# MSPM0G150X register map
Vendor: Texas Instruments; File version: This preliminary header file does not have a version number - build date: 2023-02-21 16:25:48
CPU: CM0 r0p1, little endian, MPU, no FPU, 3 interrupt priority bits
Registers are 32-bit, read-write, reset 0x0 unless marked. A register's access mark holds for its fields unless they carry their own. Offsets are from the block's base; [hi:lo] are bit positions; {n}, {i} and the like mark numbered series; <NAME> marks a mode.

## I2C0 (part 2 of 2) — PERIPHERALREGION
Base 0x400F0000
Same registers: I2C1 0x400F2000
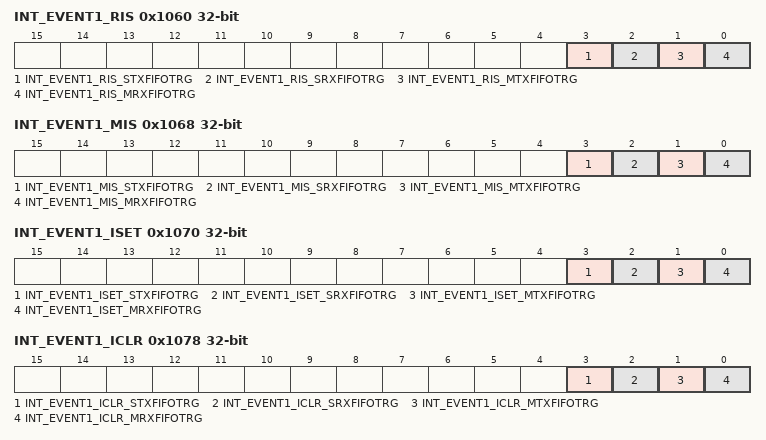
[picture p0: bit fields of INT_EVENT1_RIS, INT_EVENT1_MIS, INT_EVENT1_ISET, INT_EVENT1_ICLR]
0x1060 INT_EVENT1_RIS ro — Raw interrupt status
  [3] INT_EVENT1_RIS_STXFIFOTRG — Slave Transmit FIFO Trigger
    0=INT_EVENT1_RIS_STXFIFOTRG_CLR (CLR); 1=INT_EVENT1_RIS_STXFIFOTRG_SET (SET)
  [2] INT_EVENT1_RIS_SRXFIFOTRG — Slave Receive FIFO Trigger
    0=INT_EVENT1_RIS_SRXFIFOTRG_CLR (CLR); 1=INT_EVENT1_RIS_SRXFIFOTRG_SET (SET)
  [1] INT_EVENT1_RIS_MTXFIFOTRG — Master Transmit FIFO Trigger Trigger when Transmit FIFO contains <= defined bytes
    0=INT_EVENT1_RIS_MTXFIFOTRG_CLR (CLR); 1=INT_EVENT1_RIS_MTXFIFOTRG_SET (SET)
  [0] INT_EVENT1_RIS_MRXFIFOTRG — Master Receive FIFO Trigger Trigger when RX FIFO contains >= defined bytes
    0=INT_EVENT1_RIS_MRXFIFOTRG_CLR (CLR); 1=INT_EVENT1_RIS_MRXFIFOTRG_SET (SET)
0x1068 INT_EVENT1_MIS ro — Masked interrupt status
  [3] INT_EVENT1_MIS_STXFIFOTRG — Slave Transmit FIFO Trigger
    0=INT_EVENT1_MIS_STXFIFOTRG_CLR (CLR); 1=INT_EVENT1_MIS_STXFIFOTRG_SET (SET)
  [2] INT_EVENT1_MIS_SRXFIFOTRG — Slave Receive FIFO Trigger
    0=INT_EVENT1_MIS_SRXFIFOTRG_CLR (CLR); 1=INT_EVENT1_MIS_SRXFIFOTRG_SET (SET)
  [1] INT_EVENT1_MIS_MTXFIFOTRG — Master Transmit FIFO Trigger Trigger when Transmit FIFO contains <= defined bytes
    0=INT_EVENT1_MIS_MTXFIFOTRG_CLR (CLR); 1=INT_EVENT1_MIS_MTXFIFOTRG_SET (SET)
  [0] INT_EVENT1_MIS_MRXFIFOTRG — Master Receive FIFO Trigger Trigger when RX FIFO contains >= defined bytes
    0=INT_EVENT1_MIS_MRXFIFOTRG_CLR (CLR); 1=INT_EVENT1_MIS_MRXFIFOTRG_SET (SET)
0x1070 INT_EVENT1_ISET wo — Interrupt set
  [3] INT_EVENT1_ISET_STXFIFOTRG — Slave Transmit FIFO Trigger
    0=INT_EVENT1_ISET_STXFIFOTRG_NO_EFFECT (NO_EFFECT); 1=INT_EVENT1_ISET_STXFIFOTRG_SET (SET)
  [2] INT_EVENT1_ISET_SRXFIFOTRG — Slave Receive FIFO Trigger
    0=INT_EVENT1_ISET_SRXFIFOTRG_NO_EFFECT (NO_EFFECT); 1=INT_EVENT1_ISET_SRXFIFOTRG_SET (SET)
  [1] INT_EVENT1_ISET_MTXFIFOTRG — Master Transmit FIFO Trigger Trigger when Transmit FIFO contains <= defined bytes
    0=INT_EVENT1_ISET_MTXFIFOTRG_NO_EFFECT (NO_EFFECT); 1=INT_EVENT1_ISET_MTXFIFOTRG_SET (SET)
  [0] INT_EVENT1_ISET_MRXFIFOTRG — Master Receive FIFO Trigger Trigger when RX FIFO contains >= defined bytes
    0=INT_EVENT1_ISET_MRXFIFOTRG_NO_EFFECT (NO_EFFECT); 1=INT_EVENT1_ISET_MRXFIFOTRG_SET (SET)
0x1078 INT_EVENT1_ICLR wo — Interrupt clear
  [3] INT_EVENT1_ICLR_STXFIFOTRG — Slave Transmit FIFO Trigger
    0=INT_EVENT1_ICLR_STXFIFOTRG_NO_EFFECT (NO_EFFECT); 1=INT_EVENT1_ICLR_STXFIFOTRG_CLR (CLR)
  [2] INT_EVENT1_ICLR_SRXFIFOTRG — Slave Receive FIFO Trigger
    0=INT_EVENT1_ICLR_SRXFIFOTRG_NO_EFFECT (NO_EFFECT); 1=INT_EVENT1_ICLR_SRXFIFOTRG_CLR (CLR)
  [1] INT_EVENT1_ICLR_MTXFIFOTRG — Master Transmit FIFO Trigger Trigger when Transmit FIFO contains <= defined bytes
    0=INT_EVENT1_ICLR_MTXFIFOTRG_NO_EFFECT (NO_EFFECT); 1=INT_EVENT1_ICLR_MTXFIFOTRG_CLR (CLR)
  [0] INT_EVENT1_ICLR_MRXFIFOTRG — Master Receive FIFO Trigger Trigger when RX FIFO contains >= defined bytes
    0=INT_EVENT1_ICLR_MRXFIFOTRG_NO_EFFECT (NO_EFFECT); 1=INT_EVENT1_ICLR_MRXFIFOTRG_CLR (CLR)
0x1080 INT_EVENT2_IIDX ro — Interrupt index
  [7:0] INT_EVENT2_IIDX_STAT — I2C Module Interrupt Vector Value. This register provides the highes priority interrupt index. A read clears the corresponding interrupt flag in RIS and MISC. 15h-1Fh = Reserved
    0=INT_EVENT2_IIDX_STAT_NO_INTR (NO_INTR); 1=INT_EVENT2_IIDX_STAT_MRXFIFOTRG (MRXFIFOTRG); 2=INT_EVENT2_IIDX_STAT_MTXFIFOTRG (MTXFIFOTRG); 3=INT_EVENT2_IIDX_STAT_SRXFIFOTRG (SRXFIFOTRG); 4=INT_EVENT2_IIDX_STAT_STXFIFOTRG (STXFIFOTRG)
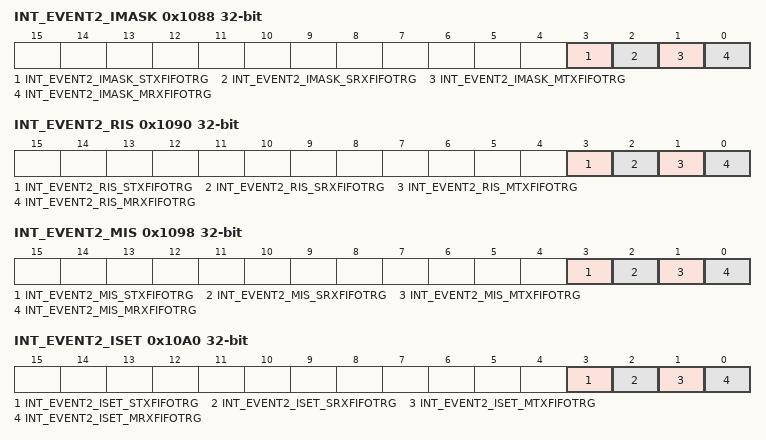
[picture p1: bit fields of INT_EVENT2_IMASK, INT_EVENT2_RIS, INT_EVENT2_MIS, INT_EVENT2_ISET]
0x1088 INT_EVENT2_IMASK — Interrupt mask
  [3] INT_EVENT2_IMASK_STXFIFOTRG — Slave Transmit FIFO Trigger
    0=INT_EVENT2_IMASK_STXFIFOTRG_CLR (CLR); 1=INT_EVENT2_IMASK_STXFIFOTRG_SET (SET)
  [2] INT_EVENT2_IMASK_SRXFIFOTRG — Slave Receive FIFO Trigger
    0=INT_EVENT2_IMASK_SRXFIFOTRG_CLR (CLR); 1=INT_EVENT2_IMASK_SRXFIFOTRG_SET (SET)
  [1] INT_EVENT2_IMASK_MTXFIFOTRG — Master Transmit FIFO Trigger Trigger when Transmit FIFO contains <= defined bytes
    0=INT_EVENT2_IMASK_MTXFIFOTRG_CLR (CLR); 1=INT_EVENT2_IMASK_MTXFIFOTRG_SET (SET)
  [0] INT_EVENT2_IMASK_MRXFIFOTRG — Master Receive FIFO Trigger Trigger when RX FIFO contains >= defined bytes
    0=INT_EVENT2_IMASK_MRXFIFOTRG_CLR (CLR); 1=INT_EVENT2_IMASK_MRXFIFOTRG_SET (SET)
0x1090 INT_EVENT2_RIS ro — Raw interrupt status
  [3] INT_EVENT2_RIS_STXFIFOTRG — Slave Transmit FIFO Trigger
    0=INT_EVENT2_RIS_STXFIFOTRG_CLR (CLR); 1=INT_EVENT2_RIS_STXFIFOTRG_SET (SET)
  [2] INT_EVENT2_RIS_SRXFIFOTRG — Slave Receive FIFO Trigger
    0=INT_EVENT2_RIS_SRXFIFOTRG_CLR (CLR); 1=INT_EVENT2_RIS_SRXFIFOTRG_SET (SET)
  [1] INT_EVENT2_RIS_MTXFIFOTRG — Master Transmit FIFO Trigger Trigger when Transmit FIFO contains <= defined bytes
    0=INT_EVENT2_RIS_MTXFIFOTRG_CLR (CLR); 1=INT_EVENT2_RIS_MTXFIFOTRG_SET (SET)
  [0] INT_EVENT2_RIS_MRXFIFOTRG — Master Receive FIFO Trigger Trigger when RX FIFO contains >= defined bytes
    0=INT_EVENT2_RIS_MRXFIFOTRG_CLR (CLR); 1=INT_EVENT2_RIS_MRXFIFOTRG_SET (SET)
0x1098 INT_EVENT2_MIS ro — Masked interrupt status
  [3] INT_EVENT2_MIS_STXFIFOTRG — Slave Transmit FIFO Trigger
    0=INT_EVENT2_MIS_STXFIFOTRG_CLR (CLR); 1=INT_EVENT2_MIS_STXFIFOTRG_SET (SET)
  [2] INT_EVENT2_MIS_SRXFIFOTRG — Slave Receive FIFO Trigger
    0=INT_EVENT2_MIS_SRXFIFOTRG_CLR (CLR); 1=INT_EVENT2_MIS_SRXFIFOTRG_SET (SET)
  [1] INT_EVENT2_MIS_MTXFIFOTRG — Master Transmit FIFO Trigger Trigger when Transmit FIFO contains <= defined bytes
    0=INT_EVENT2_MIS_MTXFIFOTRG_CLR (CLR); 1=INT_EVENT2_MIS_MTXFIFOTRG_SET (SET)
  [0] INT_EVENT2_MIS_MRXFIFOTRG — Master Receive FIFO Trigger Trigger when RX FIFO contains >= defined bytes
    0=INT_EVENT2_MIS_MRXFIFOTRG_CLR (CLR); 1=INT_EVENT2_MIS_MRXFIFOTRG_SET (SET)
0x10A0 INT_EVENT2_ISET wo — Interrupt set
  [3] INT_EVENT2_ISET_STXFIFOTRG — Slave Transmit FIFO Trigger
    0=INT_EVENT2_ISET_STXFIFOTRG_NO_EFFECT (NO_EFFECT); 1=INT_EVENT2_ISET_STXFIFOTRG_SET (SET)
  [2] INT_EVENT2_ISET_SRXFIFOTRG — Slave Receive FIFO Trigger
    0=INT_EVENT2_ISET_SRXFIFOTRG_NO_EFFECT (NO_EFFECT); 1=INT_EVENT2_ISET_SRXFIFOTRG_SET (SET)
  [1] INT_EVENT2_ISET_MTXFIFOTRG — Master Transmit FIFO Trigger Trigger when Transmit FIFO contains <= defined bytes
    0=INT_EVENT2_ISET_MTXFIFOTRG_NO_EFFECT (NO_EFFECT); 1=INT_EVENT2_ISET_MTXFIFOTRG_SET (SET)
  [0] INT_EVENT2_ISET_MRXFIFOTRG — Master Receive FIFO Trigger Trigger when RX FIFO contains >= defined bytes
    0=INT_EVENT2_ISET_MRXFIFOTRG_NO_EFFECT (NO_EFFECT); 1=INT_EVENT2_ISET_MRXFIFOTRG_SET (SET)
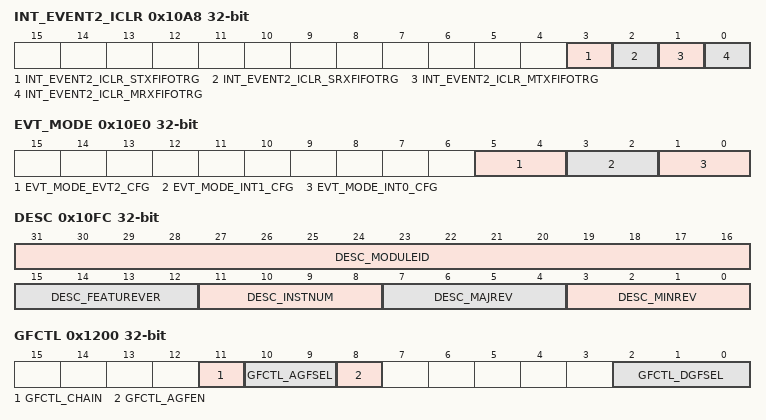
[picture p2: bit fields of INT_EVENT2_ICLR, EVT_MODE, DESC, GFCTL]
0x10A8 INT_EVENT2_ICLR wo — Interrupt clear
  [3] INT_EVENT2_ICLR_STXFIFOTRG — Slave Transmit FIFO Trigger
    0=INT_EVENT2_ICLR_STXFIFOTRG_NO_EFFECT (NO_EFFECT); 1=INT_EVENT2_ICLR_STXFIFOTRG_CLR (CLR)
  [2] INT_EVENT2_ICLR_SRXFIFOTRG — Slave Receive FIFO Trigger
    0=INT_EVENT2_ICLR_SRXFIFOTRG_NO_EFFECT (NO_EFFECT); 1=INT_EVENT2_ICLR_SRXFIFOTRG_CLR (CLR)
  [1] INT_EVENT2_ICLR_MTXFIFOTRG — Master Transmit FIFO Trigger Trigger when Transmit FIFO contains <= defined bytes
    0=INT_EVENT2_ICLR_MTXFIFOTRG_NO_EFFECT (NO_EFFECT); 1=INT_EVENT2_ICLR_MTXFIFOTRG_CLR (CLR)
  [0] INT_EVENT2_ICLR_MRXFIFOTRG — Master Receive FIFO Trigger Trigger when RX FIFO contains >= defined bytes
    0=INT_EVENT2_ICLR_MRXFIFOTRG_NO_EFFECT (NO_EFFECT); 1=INT_EVENT2_ICLR_MRXFIFOTRG_CLR (CLR)
0x10E0 EVT_MODE — Event Mode
  [5:4] EVT_MODE_EVT2_CFG ro — Event line mode select for event corresponding to [IPSTANDARD.INT_EVENT2]
    0=EVT_MODE_EVT2_CFG_DISABLE (DISABLE); 1=EVT_MODE_EVT2_CFG_SOFTWARE (SOFTWARE); 2=EVT_MODE_EVT2_CFG_HARDWARE (HARDWARE)
  [3:2] EVT_MODE_INT1_CFG ro — Event line mode select for event corresponding to [IPSTANDARD.INT_EVENT1]
    0=EVT_MODE_INT1_CFG_DISABLE (DISABLE); 1=EVT_MODE_INT1_CFG_SOFTWARE (SOFTWARE); 2=EVT_MODE_INT1_CFG_HARDWARE (HARDWARE)
  [1:0] EVT_MODE_INT0_CFG ro — Event line mode select for event corresponding to [IPSTANDARD.INT_EVENT0]
    0=EVT_MODE_INT0_CFG_DISABLE (DISABLE); 1=EVT_MODE_INT0_CFG_SOFTWARE (SOFTWARE); 2=EVT_MODE_INT0_CFG_HARDWARE (HARDWARE)
0x10E4 INTCTL — Interrupt control register
  [0] INTCTL_INTEVAL wo — Writing a 1 to this field re-evaluates the interrupt sources.
    0=INTCTL_INTEVAL_DISABLE (DISABLE); 1=INTCTL_INTEVAL_EVAL (EVAL)
0x10FC DESC ro — Module Description
  [31:16] DESC_MODULEID — Module identification contains a unique peripheral identification number. The assignments are maintained in a central database for all of the platform modules to ensure uniqueness.
  [15:12] DESC_FEATUREVER — Feature Set for the module *instance*
  [11:8] DESC_INSTNUM — Instance Number within the device. This will be a parameter to the RTL for modules that can have multiple instances
  [7:4] DESC_MAJREV — Major rev of the IP
  [3:0] DESC_MINREV — Minor rev of the IP
0x1200 GFCTL — I2C Glitch Filter Control
  [11] GFCTL_CHAIN — Analog and digital noise filters chaining enable.
    0=GFCTL_CHAIN_DISABLE (DISABLE); 1=GFCTL_CHAIN_ENABLE (ENABLE)
  [10:9] GFCTL_AGFSEL — Analog Glitch Suppression Pulse Width This field controls the pulse width select for the analog glitch suppression on SCL and SDA lines. See device datasheet for exact values. (ULP I2C only)
    0=GFCTL_AGFSEL_AGLIT_5 (AGLIT_5); 1=GFCTL_AGFSEL_AGLIT_10 (AGLIT_10); 2=GFCTL_AGFSEL_AGLIT_25 (AGLIT_25); 3=GFCTL_AGFSEL_AGLIT_50 (AGLIT_50)
  [8] GFCTL_AGFEN — Analog Glitch Suppression Enable
    0=GFCTL_AGFEN_DISABLE (DISABLE); 1=GFCTL_AGFEN_ENABLE (ENABLE)
  [2:0] GFCTL_DGFSEL — Glitch Suppression Pulse Width This field controls the pulse width select for glitch suppression on the SCL and SDA lines. The following values are the glitch suppression values in terms of functional clocks. (Core Domain only)
    0=GFCTL_DGFSEL_DISABLED (DISABLED); {v}=GFCTL_DGFSEL_CLK_{v} (CLK_{v}) (v=1..4); 5=GFCTL_DGFSEL_CLK_8 (CLK_8); 6=GFCTL_DGFSEL_CLK_16 (CLK_16); 7=GFCTL_DGFSEL_CLK_31 (CLK_31)
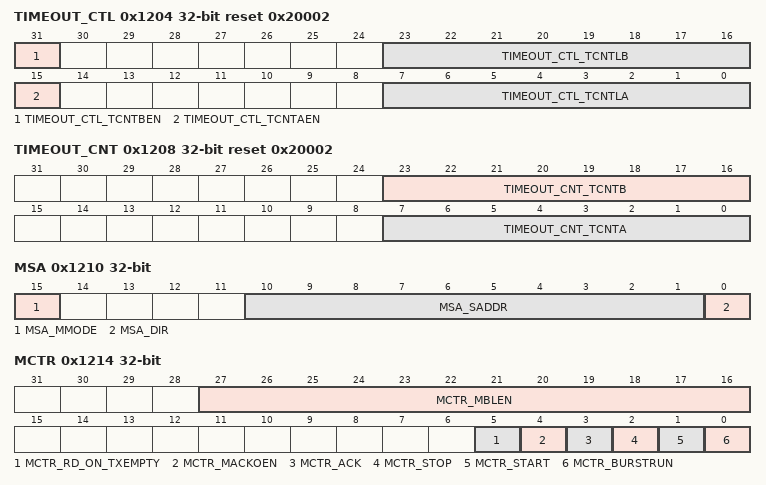
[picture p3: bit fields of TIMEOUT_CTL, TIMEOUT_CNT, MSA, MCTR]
0x1204 TIMEOUT_CTL reset 0x20002 — I2C Timeout Count Control Register
  [31] TIMEOUT_CTL_TCNTBEN — Timeout Counter B Enable
    0=TIMEOUT_CTL_TCNTBEN_DISABLE (DISABLE); 1=TIMEOUT_CTL_TCNTBEN_ENABLE (ENABLE)
  [23:16] TIMEOUT_CTL_TCNTLB — Timeout Count B Load: Counter B is used for SCL High Detection. This field contains the upper 8 bits of a 12-bit pre-load value for the Timeout B count. NOTE: The value of CNTLB must be greater than 1h. Each count is equal to 1* clock period. For example, with 10MHz functional clock one timeout period will be equal to1*100ns.
  [15] TIMEOUT_CTL_TCNTAEN — Timeout Counter A Enable
    0=TIMEOUT_CTL_TCNTAEN_DISABLE (DISABLE); 1=TIMEOUT_CTL_TCNTAEN_ENABLE (ENABLE)
  [7:0] TIMEOUT_CTL_TCNTLA — Timeout counter A load value Counter A is used for SCL low detection. This field contains the upper 8 bits of a 12-bit pre-load value for the Timeout A count. NOTE: The value of CNTLA must be greater than 1h. Each count is equal to 520 times the timeout period of functional clock. For example, with 8MHz functional clock and a 100KHz operating I2C clock, one timeout period will be equal to (1 / 8MHz) * 520 or 65 us.
0x1208 TIMEOUT_CNT ro reset 0x20002 — I2C Timeout Count Register
  [23:16] TIMEOUT_CNT_TCNTB — Timeout Count B Current Count: This field contains the upper 8 bits of a 12-bit current counter for timeout counter B
  [7:0] TIMEOUT_CNT_TCNTA — Timeout Count A Current Count: This field contains the upper 8 bits of a 12-bit current counter for timeout counter A
0x1210 MSA — I2C Master Slave Address Register
  [15] MSA_MMODE — This bit selects the adressing mode to be used in master mode When 0, 7-bit addressing is used. When 1, 10-bit addressing is used.
    0=MSA_MMODE_MODE7 (MODE7); 1=MSA_MMODE_MODE10 (MODE10)
  [10:1] MSA_SADDR — I2C Slave Address This field specifies bits A9 through A0 of the slave address. In 7-bit addressing mode as selected by MSA.MODE bit, the top 3 bits are don't care
  [0] MSA_DIR — Receive/Send The DIR bit specifies if the next master operation is a Receive (High) or Transmit (Low). 0h = Transmit 1h = Receive
    0=MSA_DIR_TRANSMIT (TRANSMIT); 1=MSA_DIR_RECEIVE (RECEIVE)
0x1214 MCTR — I2C Master Control Register
  [27:16] MCTR_MBLEN — I2C transaction length This field contains the programmed length of bytes of the Transaction.
  [5] MCTR_RD_ON_TXEMPTY — Read on TX Empty
    0=MCTR_RD_ON_TXEMPTY_DISABLE (DISABLE); 1=MCTR_RD_ON_TXEMPTY_ENABLE (ENABLE)
  [4] MCTR_MACKOEN — Master ACK overrride Enable
    0=MCTR_MACKOEN_DISABLE (DISABLE); 1=MCTR_MACKOEN_ENABLE (ENABLE)
  [3] MCTR_ACK — Data Acknowledge Enable. Software needs to configure this bit to send the ACK or NACK. See field decoding in Table: MCTR Field decoding.
    0=MCTR_ACK_DISABLE (DISABLE); 1=MCTR_ACK_ENABLE (ENABLE)
  [2] MCTR_STOP — Generate STOP
    0=MCTR_STOP_DISABLE (DISABLE); 1=MCTR_STOP_ENABLE (ENABLE)
  [1] MCTR_START — Generate START
    0=MCTR_START_DISABLE (DISABLE); 1=MCTR_START_ENABLE (ENABLE)
  [0] MCTR_BURSTRUN — I2C Master Enable and start transaction
    0=MCTR_BURSTRUN_DISABLE (DISABLE); 1=MCTR_BURSTRUN_ENABLE (ENABLE)
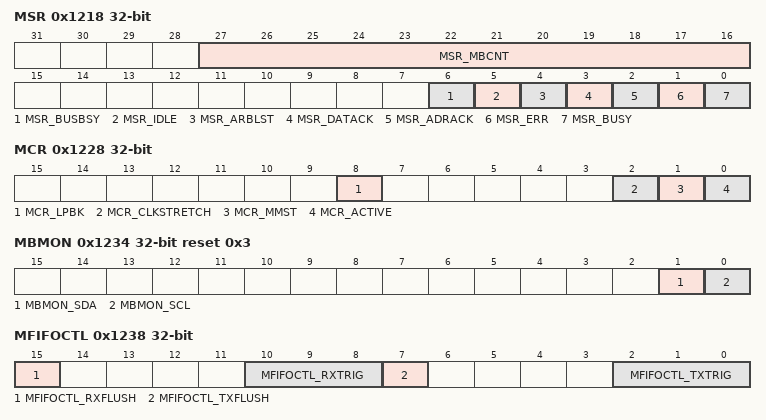
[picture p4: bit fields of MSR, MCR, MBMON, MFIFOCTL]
0x1218 MSR ro — I2C Master Status Register
  [27:16] MSR_MBCNT — I2C Master Transaction Count This field contains the current count-down value of the transaction.
  [6] MSR_BUSBSY — I2C Bus is Busy Master State Machine will wait until this bit is cleared before starting a transaction. When first enabling the Master in multi master environments, FW should wait for one I2C clock period after setting ACTIVE high before writing to the MTCR register to start the transaction so that if SCL goes low it will trigger the BUSBSY.
    0=MSR_BUSBSY_CLEARED (CLEARED); 1=MSR_BUSBSY_SET (SET)
  [5] MSR_IDLE — I2C Idle
    0=MSR_IDLE_CLEARED (CLEARED); 1=MSR_IDLE_SET (SET)
  [4] MSR_ARBLST — Arbitration Lost
    0=MSR_ARBLST_CLEARED (CLEARED); 1=MSR_ARBLST_SET (SET)
  [3] MSR_DATACK — Acknowledge Data
    0=MSR_DATACK_CLEARED (CLEARED); 1=MSR_DATACK_SET (SET)
  [2] MSR_ADRACK — Acknowledge Address
    0=MSR_ADRACK_CLEARED (CLEARED); 1=MSR_ADRACK_SET (SET)
  [1] MSR_ERR — Error The error can be from the slave address not being acknowledged or the transmit data not being acknowledged.
    0=MSR_ERR_CLEARED (CLEARED); 1=MSR_ERR_SET (SET)
  [0] MSR_BUSY — I2C Master FSM Busy The BUSY bit is set during an ongoing transaction, so is set during the transmit/receive of the amount of data set in MBLEN including START, RESTART, Address and STOP signal generation when required for the current transaction.
    0=MSR_BUSY_CLEARED (CLEARED); 1=MSR_BUSY_SET (SET)
0x121C MRXDATA ro — I2C Master RXData
  [7:0] MRXDATA_VALUE — Received Data. This field contains the last received data.
0x1220 MTXDATA — I2C Master TXData
  [7:0] MTXDATA_VALUE — Transmit Data This byte contains the data to be transferred during the next transaction.
0x1224 MTPR reset 0x1 — I2C Master Timer Period
  [6:0] MTPR_TPR — Timer Period This field is used in the equation to configure SCL_PERIOD : SCL_PERIOD = (1 + TPR ) * (SCL_LP + SCL_HP ) * INT_CLK_PRD where: SCL_PRD is the SCL line period (I2C clock). TPR is the Timer Period register value (range of 1 to 127). SCL_LP is the SCL Low period (fixed at 6). SCL_HP is the SCL High period (fixed at 4). CLK_PRD is the functional clock period in ns.
0x1228 MCR — I2C Master Configuration
  [8] MCR_LPBK — I2C Loopback
    0=MCR_LPBK_DISABLE (DISABLE); 1=MCR_LPBK_ENABLE (ENABLE)
  [2] MCR_CLKSTRETCH — Clock Stretching. This bit controls the support for clock stretching of the I2C bus.
    0=MCR_CLKSTRETCH_DISABLE (DISABLE); 1=MCR_CLKSTRETCH_ENABLE (ENABLE)
  [1] MCR_MMST — Multimaster mode. In Multimaster mode the SCL high time counts once the SCL line has been detected high. If this is not enabled the high time counts as soon as the SCL line has been set high by the I2C controller.
    0=MCR_MMST_DISABLE (DISABLE); 1=MCR_MMST_ENABLE (ENABLE)
  [0] MCR_ACTIVE — Device Active After this bit has been set, it should not be set again unless it has been cleared by writing a 0 or by a reset, otherwise transfer failures may occur.
    0=MCR_ACTIVE_DISABLE (DISABLE); 1=MCR_ACTIVE_ENABLE (ENABLE)
0x1234 MBMON ro reset 0x3 — I2C Master Bus Monitor
  [1] MBMON_SDA — I2C SDA Status
    0=MBMON_SDA_CLEARED (CLEARED); 1=MBMON_SDA_SET (SET)
  [0] MBMON_SCL — I2C SCL Status
    0=MBMON_SCL_CLEARED (CLEARED); 1=MBMON_SCL_SET (SET)
0x1238 MFIFOCTL — I2C Master FIFO Control
  [15] MFIFOCTL_RXFLUSH — RX FIFO Flush Setting this bit will Flush the RX FIFO. Before reseting this bit to stop Flush the RXFIFOCNT should be checked to be 0 and indicating that the Flush has completed.
    0=MFIFOCTL_RXFLUSH_NOFLUSH (NOFLUSH); 1=MFIFOCTL_RXFLUSH_FLUSH (FLUSH)
  [10:8] MFIFOCTL_RXTRIG — RX FIFO Trigger Indicates at what fill level in the RX FIFO a trigger will be generated. Note: Programming RXTRIG to 0x0 has no effect since no data is present to transfer out of RX FIFO.
    {v}=MFIFOCTL_RXTRIG_LEVEL_{v+1} (LEVEL_{v+1}) (v=4..7)
  [7] MFIFOCTL_TXFLUSH — TX FIFO Flush Setting this bit will Flush the TX FIFO. Before reseting this bit to stop Flush the TXFIFOCNT should be checked to be 8 and indicating that the Flush has completed.
    0=MFIFOCTL_TXFLUSH_NOFLUSH (NOFLUSH); 1=MFIFOCTL_TXFLUSH_FLUSH (FLUSH)
  [2:0] MFIFOCTL_TXTRIG — TX FIFO Trigger Indicates at what fill level in the TX FIFO a trigger will be generated.
    {v}=MFIFOCTL_TXTRIG_LEVEL_{v} (LEVEL_{v}) (v=4..7)
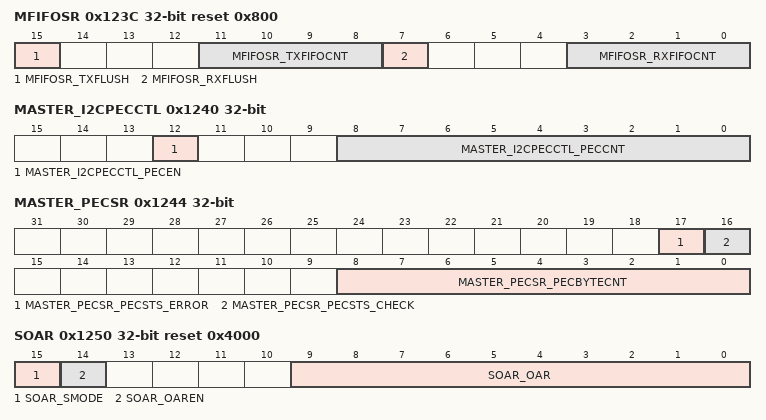
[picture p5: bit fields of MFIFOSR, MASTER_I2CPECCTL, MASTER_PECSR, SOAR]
0x123C MFIFOSR ro reset 0x800 — I2C Master FIFO Status Register
  [15] MFIFOSR_TXFLUSH — TX FIFO Flush When this bit is set a Flush operation for the TX FIFO is active. Clear the TXFLUSH bit in the control register to stop.
    0=MFIFOSR_TXFLUSH_INACTIVE (INACTIVE); 1=MFIFOSR_TXFLUSH_ACTIVE (ACTIVE)
  [11:8] MFIFOSR_TXFIFOCNT — Number of Bytes which could be put into the TX FIFO
  [7] MFIFOSR_RXFLUSH — RX FIFO Flush When this bit is set a Flush operation for the RX FIFO is active. Clear the RXFLUSH bit in the control register to stop.
    0=MFIFOSR_RXFLUSH_INACTIVE (INACTIVE); 1=MFIFOSR_RXFLUSH_ACTIVE (ACTIVE)
  [3:0] MFIFOSR_RXFIFOCNT — Number of Bytes which could be read from the RX FIFO
0x1240 MASTER_I2CPECCTL — I2C master PEC control register
  [12] MASTER_I2CPECCTL_PECEN — PEC Enable This bit enables the SMB Packet Error Checking (PEC). When enabled the PEC is calculated on all bits accept the Start, Stop, Ack and Nack. The PEC LSFR and the Byte Counter is set to 0 when the State Machine is in the IDLE state, which occur following a Stop or when a timeout occurs. The Counter is also set to 0 after the PEC byte is sent or received. Note that the NACK is automatically send following a PEC byte that results in a PEC error. The PEC Polynomial is x^8 + x^2 + x^1 + 1.
    0=MASTER_I2CPECCTL_PECEN_DISABLE (DISABLE); 1=MASTER_I2CPECCTL_PECEN_ENABLE (ENABLE)
  [8:0] MASTER_I2CPECCTL_PECCNT — PEC Count When this field is non zero, the number of I2C bytes are counted (Note that although the PEC is calculated on the I2C address it is not counted at a byte). When the byte count = PECCNT and the state machine is transmitting, the contents of the LSFR is loaded into the shift register instead of the byte received from the Tx FIFO. When the state machine is receiving, after the last bit of this byte is received the LSFR is checked and if it is non-zero, a PEC RX Error interrupt is generated. The I2C packet must be padded to include the PEC byte for both transmit and receive. In transmit mode the FIFO must be loaded with a dummy PEC byte. In receive mode the PEC byte will be passed to the Rx FIFO. In the normal Master use case, FW would set PECEN=1 and PECCNT=SMB packet length (Not including Slave Address byte, but including the PEC byte). FW would then configure DMA to allow the packet to complete unassisted and write MCTR to initiate the transaction. Note that when the byte count = PEC CNT, the byte count is reset to 0 and multiple PEC calculation can automatically occur within a single I2C transaction. Note that any write to the MASTER_I2CPECCTL Register will clear the current PEC Byte Count in the Master State Machine.
0x1244 MASTER_PECSR ro — I2C master PEC status register
  [17] MASTER_PECSR_PECSTS_ERROR — This status bit indicates if a PEC check error occurred in the transaction that occurred before the last Stop. Latched on Stop.
    0=MASTER_PECSR_PECSTS_ERROR_CLEARED (CLEARED); 1=MASTER_PECSR_PECSTS_ERROR_SET (SET)
  [16] MASTER_PECSR_PECSTS_CHECK — This status bit indicates if the PEC was checked in the transaction that occurred before the last Stop. Latched on Stop.
    0=MASTER_PECSR_PECSTS_CHECK_CLEARED (CLEARED); 1=MASTER_PECSR_PECSTS_CHECK_SET (SET)
  [8:0] MASTER_PECSR_PECBYTECNT — PEC Byte Count This is the current PEC Byte Count of the Master State Machine.
0x1250 SOAR reset 0x4000 — I2C Slave Own Address
  [15] SOAR_SMODE — This bit selects the adressing mode to be used in slave mode. When 0, 7-bit addressing is used. When 1, 10-bit addressing is used.
    0=SOAR_SMODE_MODE7 (MODE7); 1=SOAR_SMODE_MODE10 (MODE10)
  [14] SOAR_OAREN — I2C Slave Own Address Enable
    0=SOAR_OAREN_DISABLE (DISABLE); 1=SOAR_OAREN_ENABLE (ENABLE)
  [9:0] SOAR_OAR — I2C Slave Own Address: This field specifies bits A9 through A0 of the slave address. In 7-bit addressing mode as selected by I2CSOAR.MODE bit, the top 3 bits are don't care
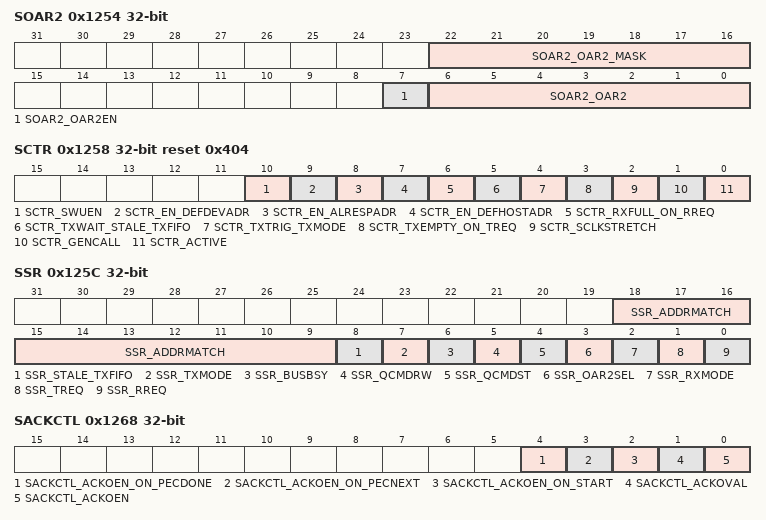
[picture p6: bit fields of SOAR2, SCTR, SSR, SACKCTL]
0x1254 SOAR2 — I2C Slave Own Address 2
  [22:16] SOAR2_OAR2_MASK — I2C Slave Own Address 2 Mask: This field specifies bits A6 through A0 of the slave address. The bits with value 1 in SOAR2.OAR2_MASK field will make the corresponding incoming address bits to match by default regardless of the value inside SOAR2.OAR2 i.e. corresponding SOAR2.OAR2 bit is a dont care.
  [7] SOAR2_OAR2EN — I2C Slave Own Address 2 Enable
    0=SOAR2_OAR2EN_DISABLE (DISABLE); 1=SOAR2_OAR2EN_ENABLE (ENABLE)
  [6:0] SOAR2_OAR2 — I2C Slave Own Address 2 This field specifies the alternate OAR2 address.
0x1258 SCTR reset 0x404 — I2C Slave Control Register
  [10] SCTR_SWUEN — Slave Wakeup Enable
    0=SCTR_SWUEN_DISABLE (DISABLE); 1=SCTR_SWUEN_ENABLE (ENABLE)
  [9] SCTR_EN_DEFDEVADR — Enable Deault device address
    0=SCTR_EN_DEFDEVADR_DISABLE (DISABLE); 1=SCTR_EN_DEFDEVADR_ENABLE (ENABLE)
  [8] SCTR_EN_ALRESPADR — Enable Alert Response Address
    0=SCTR_EN_ALRESPADR_DISABLE (DISABLE); 1=SCTR_EN_ALRESPADR_ENABLE (ENABLE)
  [7] SCTR_EN_DEFHOSTADR — Enable Default Host Address
    0=SCTR_EN_DEFHOSTADR_DISABLE (DISABLE); 1=SCTR_EN_DEFHOSTADR_ENABLE (ENABLE)
  [6] SCTR_RXFULL_ON_RREQ — Rx full interrupt generated on RREQ condition as indicated in SSR
    0=SCTR_RXFULL_ON_RREQ_DISABLE (DISABLE); 1=SCTR_RXFULL_ON_RREQ_ENABLE (ENABLE)
  [5] SCTR_TXWAIT_STALE_TXFIFO — Tx transfer waits when stale data in Tx FIFO. This prevents stale bytes left in the TX FIFO from automatically being sent on the next I2C packet. Note: this should be used with TXEMPTY_ON_TREQ set to prevent the Slave State Machine from waiting for TX FIFO data without an interrupt notification when the FIFO data is stale.
    0=SCTR_TXWAIT_STALE_TXFIFO_DISABLE (DISABLE); 1=SCTR_TXWAIT_STALE_TXFIFO_ENABLE (ENABLE)
  [4] SCTR_TXTRIG_TXMODE — Tx Trigger when slave FSM is in Tx Mode
    0=SCTR_TXTRIG_TXMODE_DISABLE (DISABLE); 1=SCTR_TXTRIG_TXMODE_ENABLE (ENABLE)
  [3] SCTR_TXEMPTY_ON_TREQ — Tx Empty Interrupt on TREQ
    0=SCTR_TXEMPTY_ON_TREQ_DISABLE (DISABLE); 1=SCTR_TXEMPTY_ON_TREQ_ENABLE (ENABLE)
  [2] SCTR_SCLKSTRETCH — Slave Clock Stretch Enable
    0=SCTR_SCLKSTRETCH_DISABLE (DISABLE); 1=SCTR_SCLKSTRETCH_ENABLE (ENABLE)
  [1] SCTR_GENCALL — General call response enable. This bit is only available in UCBxI2COA0. Modify only when UCSWRST = 1. 0b = Do not respond to a general call 1b = Respond to a general call
    0=SCTR_GENCALL_DISABLE (DISABLE); 1=SCTR_GENCALL_ENABLE (ENABLE)
  [0] SCTR_ACTIVE — Device Active. Setting this bit enables the slave functionality.
    0=SCTR_ACTIVE_DISABLE (DISABLE); 1=SCTR_ACTIVE_ENABLE (ENABLE)
0x125C SSR ro — I2C Slave Status Register
  [18:9] SSR_ADDRMATCH — Indicates the address for which slave address match happened
  [8] SSR_STALE_TXFIFO — Stale Tx FIFO
    0=SSR_STALE_TXFIFO_CLEARED (CLEARED); 1=SSR_STALE_TXFIFO_SET (SET)
  [7] SSR_TXMODE — Slave FSM is in TX MODE
    0=SSR_TXMODE_CLEARED (CLEARED); 1=SSR_TXMODE_SET (SET)
  [6] SSR_BUSBSY — I2C bus is busy
    0=SSR_BUSBSY_CLEARED (CLEARED); 1=SSR_BUSBSY_SET (SET)
  [5] SSR_QCMDRW — Quick Command Read / Write This bit only has meaning when the QCMDST bit is set. Value Description: 0: Quick command was a write 1: Quick command was a read
    0=SSR_QCMDRW_CLEARED (CLEARED); 1=SSR_QCMDRW_SET (SET)
  [4] SSR_QCMDST — Quick Command Status Value Description: 0: The last transaction was a normal transaction or a transaction has not occurred. 1: The last transaction was a Quick Command transaction
    0=SSR_QCMDST_CLEARED (CLEARED); 1=SSR_QCMDST_SET (SET)
  [3] SSR_OAR2SEL — OAR2 Address Matched This bit gets reevaluated after every address comparison.
    0=SSR_OAR2SEL_CLEARED (CLEARED); 1=SSR_OAR2SEL_SET (SET)
  [2] SSR_RXMODE — Slave FSM is in Rx MODE
    0=SSR_RXMODE_CLEARED (CLEARED); 1=SSR_RXMODE_SET (SET)
  [1] SSR_TREQ — Transmit Request
    0=SSR_TREQ_CLEARED (CLEARED); 1=SSR_TREQ_SET (SET)
  [0] SSR_RREQ — Receive Request
    0=SSR_RREQ_CLEARED (CLEARED); 1=SSR_RREQ_SET (SET)
0x1260 SRXDATA ro — I2C Slave RXData
  [7:0] SRXDATA_VALUE — Received Data. This field contains the last received data.
0x1264 STXDATA — I2C Slave TXData
  [7:0] STXDATA_VALUE — Transmit Data This byte contains the data to be transferred during the next transaction.
0x1268 SACKCTL — I2C Slave ACK Control
  [4] SACKCTL_ACKOEN_ON_PECDONE — When set this bit will automatically turn on the Slave ACKOEN field following the ACK/NACK of the received PEC byte.
    0=SACKCTL_ACKOEN_ON_PECDONE_DISABLE (DISABLE); 1=SACKCTL_ACKOEN_ON_PECDONE_ENABLE (ENABLE)
  [3] SACKCTL_ACKOEN_ON_PECNEXT — When set this bit will automatically turn on the Slave ACKOEN field following the ACK/NACK of the byte received just prior to the PEC byte. Note that when ACKOEN is set the PEC byte will not automatically be ACKed/NACKed by the State Machine and FW must perform this function by writing SLAVE_SACKCTL.
    0=SACKCTL_ACKOEN_ON_PECNEXT_DISABLE (DISABLE); 1=SACKCTL_ACKOEN_ON_PECNEXT_ENABLE (ENABLE)
  [2] SACKCTL_ACKOEN_ON_START — When set this bit will automatically turn on the Slave ACKOEN field following a Start Condition.
    0=SACKCTL_ACKOEN_ON_START_DISABLE (DISABLE); 1=SACKCTL_ACKOEN_ON_START_ENABLE (ENABLE)
  [1] SACKCTL_ACKOVAL — I2C Slave ACK Override Value Note: for General Call this bit will be ignored if set to NACK and slave continues to receive data.
    0=SACKCTL_ACKOVAL_DISABLE (DISABLE); 1=SACKCTL_ACKOVAL_ENABLE (ENABLE)
  [0] SACKCTL_ACKOEN — I2C Slave ACK Override Enable
    0=SACKCTL_ACKOEN_DISABLE (DISABLE); 1=SACKCTL_ACKOEN_ENABLE (ENABLE)
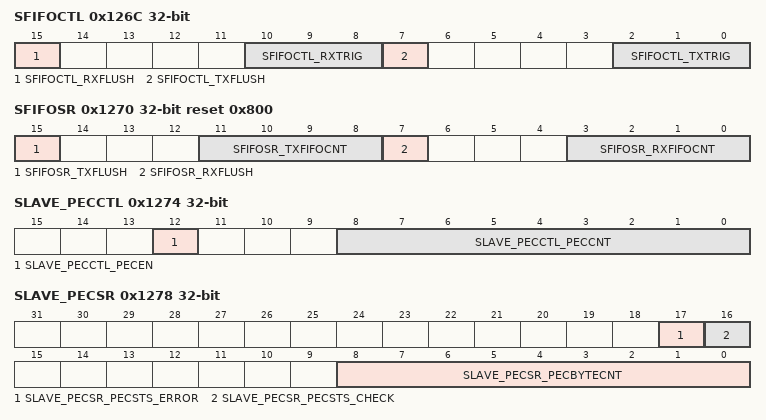
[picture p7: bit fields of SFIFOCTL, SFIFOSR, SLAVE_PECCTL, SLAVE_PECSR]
0x126C SFIFOCTL — I2C Slave FIFO Control
  [15] SFIFOCTL_RXFLUSH — RX FIFO Flush Setting this bit will Flush the RX FIFO. Before reseting this bit to stop Flush the RXFIFOCNT should be checked to be 0 and indicating that the Flush has completed.
    0=SFIFOCTL_RXFLUSH_NOFLUSH (NOFLUSH); 1=SFIFOCTL_RXFLUSH_FLUSH (FLUSH)
  [10:8] SFIFOCTL_RXTRIG — RX FIFO Trigger Indicates at what fill level in the RX FIFO a trigger will be generated. Note: Programming RXTRIG to 0x0 has no effect since no data is present to transfer out of RX FIFO.
    {v}=SFIFOCTL_RXTRIG_LEVEL_{v+1} (LEVEL_{v+1}) (v=4..7)
  [7] SFIFOCTL_TXFLUSH — TX FIFO Flush Setting this bit will Flush the TX FIFO. Before reseting this bit to stop Flush the TXFIFOCNT should be checked to be 8 and indicating that the Flush has completed.
    0=SFIFOCTL_TXFLUSH_NOFLUSH (NOFLUSH); 1=SFIFOCTL_TXFLUSH_FLUSH (FLUSH)
  [2:0] SFIFOCTL_TXTRIG — TX FIFO Trigger Indicates at what fill level in the TX FIFO a trigger will be generated.
    {v}=SFIFOCTL_TXTRIG_LEVEL_{v} (LEVEL_{v}) (v=4..7)
0x1270 SFIFOSR ro reset 0x800 — I2C Slave FIFO Status Register
  [15] SFIFOSR_TXFLUSH — TX FIFO Flush When this bit is set a Flush operation for the TX FIFO is active. Clear the TXFLUSH bit in the control register to stop.
    0=SFIFOSR_TXFLUSH_INACTIVE (INACTIVE); 1=SFIFOSR_TXFLUSH_ACTIVE (ACTIVE)
  [11:8] SFIFOSR_TXFIFOCNT — Number of Bytes which could be put into the TX FIFO
  [7] SFIFOSR_RXFLUSH — RX FIFO Flush When this bit is set a Flush operation for the RX FIFO is active. Clear the RXFLUSH bit in the control register to stop.
    0=SFIFOSR_RXFLUSH_INACTIVE (INACTIVE); 1=SFIFOSR_RXFLUSH_ACTIVE (ACTIVE)
  [3:0] SFIFOSR_RXFIFOCNT — Number of Bytes which could be read from the RX FIFO
0x1274 SLAVE_PECCTL — I2C Slave PEC control register
  [12] SLAVE_PECCTL_PECEN — PEC Enable This bit enables the SMB Packet Error Checking (PEC). When enabled the PEC is calculated on all bits accept the Start, Stop, Ack and Nack. The PEC LSFR and the Byte Counter is set to 0 when the State Machine is in the IDLE state, which occur following a Stop or when a timeout occurs. The Counter is also set to 0 after the PEC byte is sent or received. Note that the NACK is automatically send following a PEC byte that results in a PEC error. The PEC Polynomial is x^8 + x^2 + x^1 + 1.
    0=SLAVE_PECCTL_PECEN_DISABLE (DISABLE); 1=SLAVE_PECCTL_PECEN_ENABLE (ENABLE)
  [8:0] SLAVE_PECCTL_PECCNT — When this field is non zero, the number of I2C data bytes are counted. When the byte count = PECCNT and the state machine is transmitting, the contents of the LSFR is loaded into the shift register instead of the byte received from the Tx FIFO. When the state machine is receiving, after the last bit of this byte is received the LSFR is checked and if it is non-zero, a PEC RX Error interrupt is generated. The I2C packet must be padded to include the PEC byte for both transmit and receive. In transmit mode the FIFO must be loaded with a dummy PEC byte. In receive mode the PEC byte will be passed to the Rx FIFO. In the normal Slave use case, FW would set PECEN=1 and PECCNT=0 and use the ACKOEN until the remaining SMB packet length is known. FW would then set the PECCNT to the remaining packet length (Including PEC bye). FW would then configure DMA to allow the packet to complete unassisted and exit NoAck mode. Note that when the byte count = PEC CNT, the byte count is reset to 0 and multiple PEC calculation can automatically occur within a single I2C transaction
0x1278 SLAVE_PECSR ro — I2C slave PEC status register
  [17] SLAVE_PECSR_PECSTS_ERROR — This status bit indicates if a PEC check error occurred in the transaction that occurred before the last Stop. Latched on Stop.
    0=SLAVE_PECSR_PECSTS_ERROR_CLEARED (CLEARED); 1=SLAVE_PECSR_PECSTS_ERROR_SET (SET)
  [16] SLAVE_PECSR_PECSTS_CHECK — This status bit indicates if the PEC was checked in the transaction that occurred before the last Stop. Latched on Stop.
    0=SLAVE_PECSR_PECSTS_CHECK_CLEARED (CLEARED); 1=SLAVE_PECSR_PECSTS_CHECK_SET (SET)
  [8:0] SLAVE_PECSR_PECBYTECNT — This is the current PEC Byte Count of the Slave State Machine.

## Notices in the file
Copyright (C) 2023 Texas Instruments Incorporated - http://www.ti.com
Redistribution and use in source and binary forms, with or without
modification, are permitted provided that the following conditions
are met:
Redistributions of source code must retain the above copyright
notice, this list of conditions and the following disclaimer.
Redistributions in binary form must reproduce the above copyright
notice, this list of conditions and the following disclaimer in the
documentation and/or other materials provided with the
distribution.
Neither the name of Texas Instruments Incorporated nor the names of
its contributors may be used to endorse or promote products derived
from this software without specific prior written permission.
THIS SOFTWARE IS PROVIDED BY THE COPYRIGHT HOLDERS AND CONTRIBUTORS
"AS IS" AND ANY EXPRESS OR IMPLIED WARRANTIES, INCLUDING, BUT NOT
LIMITED TO, THE IMPLIED WARRANTIES OF MERCHANTABILITY AND FITNESS FOR
A PARTICULAR PURPOSE ARE DISCLAIMED. IN NO EVENT SHALL THE COPYRIGHT
OWNER OR CONTRIBUTORS BE LIABLE FOR ANY DIRECT, INDIRECT, INCIDENTAL,
SPECIAL, EXEMPLARY, OR CONSEQUENTIAL DAMAGES (INCLUDING, BUT NOT
LIMITED TO, PROCUREMENT OF SUBSTITUTE GOODS OR SERVICES; LOSS OF USE,
DATA, OR PROFITS; OR BUSINESS INTERRUPTION) HOWEVER CAUSED AND ON ANY
THEORY OF LIABILITY, WHETHER IN CONTRACT, STRICT LIABILITY, OR TORT
(INCLUDING NEGLIGENCE OR OTHERWISE) ARISING IN ANY WAY OUT OF THE USE
OF THIS SOFTWARE, EVEN IF ADVISED OF THE POSSIBILITY OF SUCH DAMAGE.
